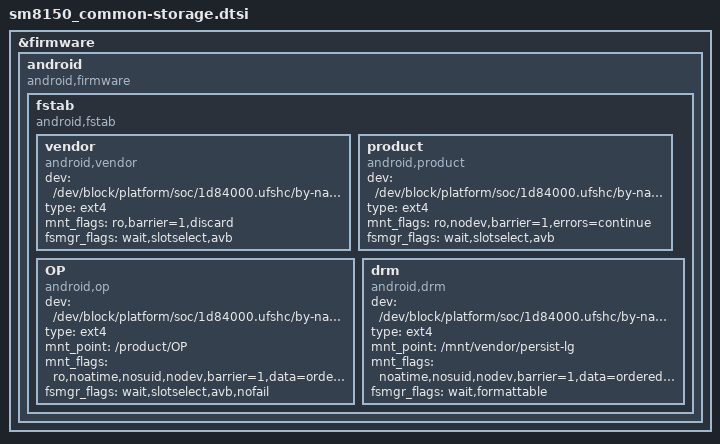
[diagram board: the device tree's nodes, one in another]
/*
 * Copyright (c) 2018, The Linux Foundation. All rights reserved.
 *
 * This program is free software; you can redistribute it and/or modify
 * it under the terms of the GNU General Public License version 2 and
 * only version 2 as published by the Free Software Foundation.
 *
 * This program is distributed in the hope that it will be useful,
 * but WITHOUT ANY WARRANTY; without even the implied warranty of
 * MERCHANTABILITY or FITNESS FOR A PARTICULAR PURPOSE.  See the
 * GNU General Public License for more details.
 */

&firmware {
	android {
		compatible = "android,firmware";
		fstab {
			compatible = "android,fstab";
			vendor {
				compatible = "android,vendor";
				dev = "/dev/block/platform/soc/1d84000.ufshc/by-name/vendor";
				type = "ext4";
				mnt_flags = "ro,barrier=1,discard";
				fsmgr_flags = "wait,slotselect,avb";
				status = "ok";
			};
			product {
				compatible = "android,product";
				dev = "/dev/block/platform/soc/1d84000.ufshc/by-name/product";
				type = "ext4";
				mnt_flags = "ro,nodev,barrier=1,errors=continue";
				fsmgr_flags = "wait,slotselect,avb";
				status = "ok";
			};
			OP {
				compatible = "android,op";
				dev = "/dev/block/platform/soc/1d84000.ufshc/by-name/OP";
				type = "ext4";
				mnt_point = "/product/OP";
				mnt_flags = "ro,noatime,nosuid,nodev,barrier=1,data=ordered,noauto_da_alloc";
				fsmgr_flags = "wait,slotselect,avb,nofail";
				status = "ok";
			};
			drm {
				compatible = "android,drm";
				dev = "/dev/block/platform/soc/1d84000.ufshc/by-name/drm";
				type = "ext4";
				mnt_point = "/mnt/vendor/persist-lg";
				mnt_flags = "noatime,nosuid,nodev,barrier=1,data=ordered,noauto_da_alloc,errors=continue";
				fsmgr_flags = "wait,formattable";
				status = "ok";
			};
		};
	};
};

